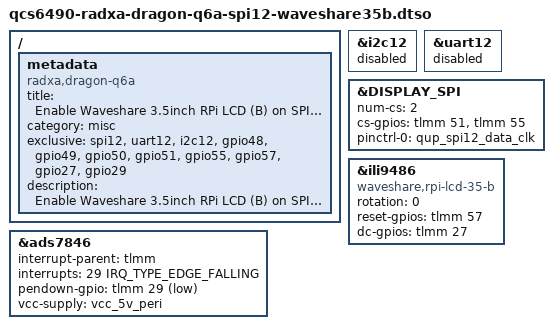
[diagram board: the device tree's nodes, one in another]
#define DISPLAY_SPI spi12
#include "waveshare35-lcd.dtsi"

/ {
    metadata {
        title = "Enable Waveshare 3.5inch RPi LCD (B) on SPI12";
        compatible = "radxa,dragon-q6a";
        category = "misc";
        exclusive = "spi12", "uart12", "i2c12", "gpio48", "gpio49", "gpio50", "gpio51", "gpio55", "gpio57", "gpio27", "gpio29";
        description = "Enable Waveshare 3.5inch RPi LCD (B) on SPI12.";
    };
};

&i2c12 {
	status = "disabled";
};

&uart12 {
	status = "disabled";
};

&DISPLAY_SPI {
	num-cs = <2>;
	cs-gpios = <&tlmm 51 GPIO_ACTIVE_HIGH
				&tlmm 55 GPIO_ACTIVE_HIGH>;
	pinctrl-names = "default", "high_speed";
	pinctrl-0 = <&qup_spi12_data_clk>;
};

&ili9486 {
	compatible = "waveshare,rpi-lcd-35-b", "ilitek,ili9486";
	rotation = <0>;

	reset-gpios = <&tlmm 57 GPIO_ACTIVE_HIGH>;
	dc-gpios = <&tlmm 27 GPIO_ACTIVE_HIGH>;
};

&ads7846 {
	interrupt-parent = <&tlmm>;
	interrupts = <29 IRQ_TYPE_EDGE_FALLING>;
	pendown-gpio = <&tlmm 29 GPIO_ACTIVE_LOW>;
	vcc-supply = <&vcc_5v_peri>;
};
